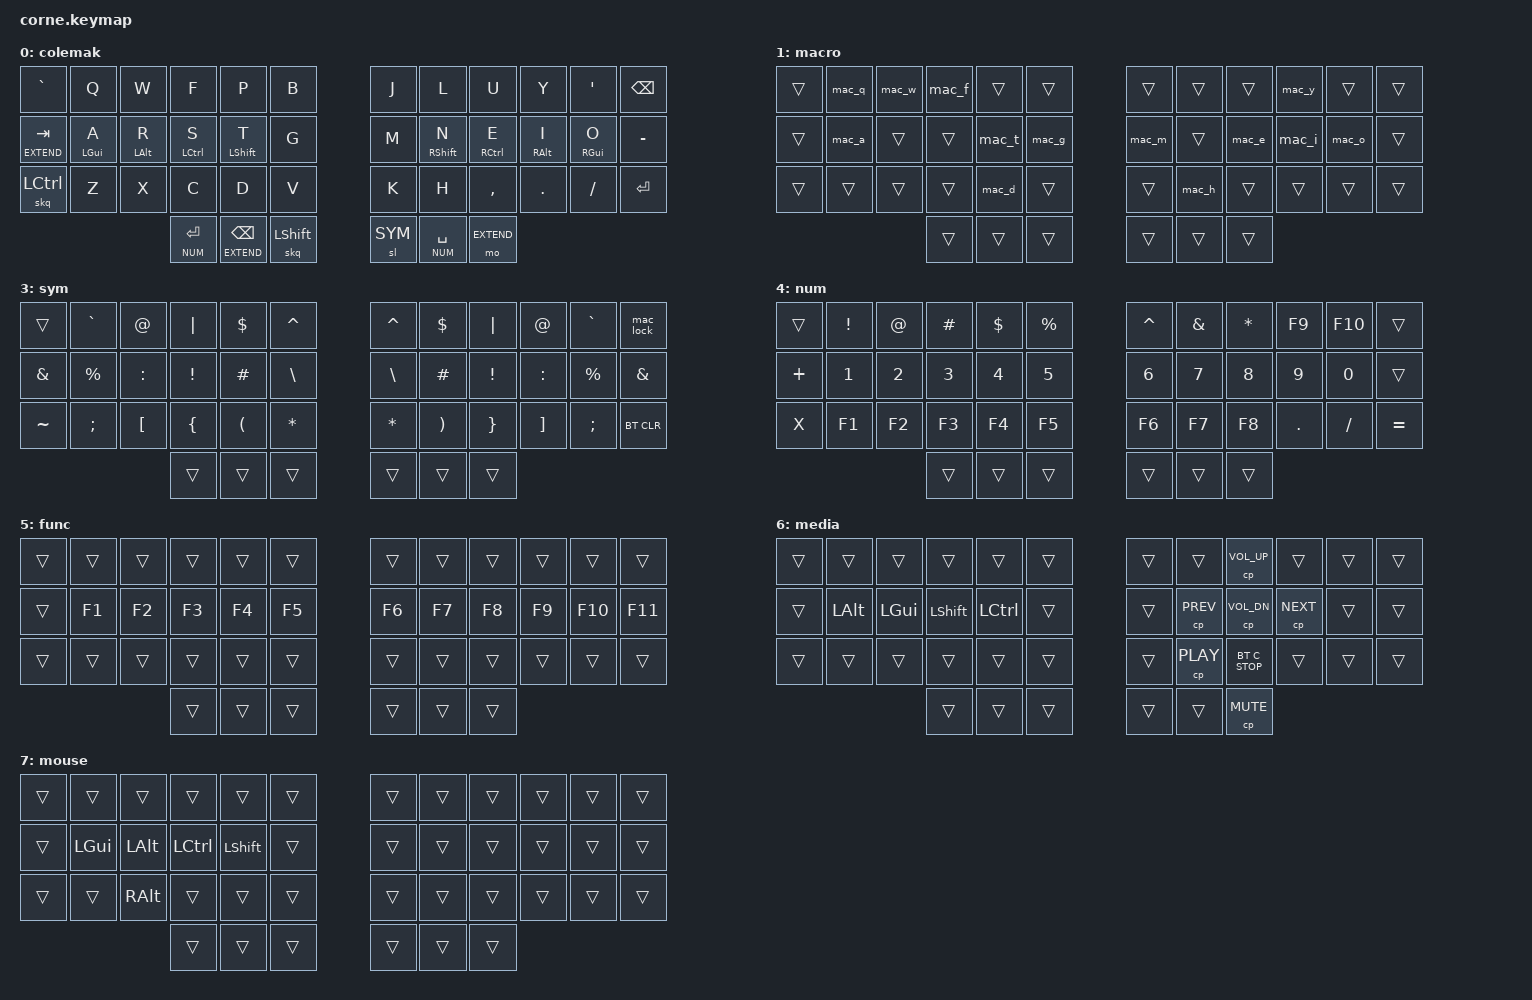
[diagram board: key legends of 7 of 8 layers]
#include <behaviors.dtsi>
#include <dt-bindings/zmk/keys.h>
#include <dt-bindings/zmk/bt.h>
#include <dt-bindings/zmk/ext_power.h>
#include <dt-bindings/zmk/outputs.h>

// Layer Definitions
#define COLEMAK 0
#define MACRO 1
#define EXTEND 2
#define SYM 3
#define NUM 4
#define FUNC 5
#define MEDIA 6
#define MOUSE 7

// Macros
#define AS(keycode) &as LS(keycode) keycode     // Autoshift Macro				

// To do
// - find a place for FUNC, MEDIA, and MOUSE to be toggled, maybe both thumbs toggles a selection layer?

// Backspace/delete multiple on double tap hold
&lt {
    tapping-term-ms = <250>;
    quick_tap_ms = <200>;
    flavor = "tap-preferred";
};

/ {
    // Behavior configuration from https://zmk.dev/docs/behaviors/hold-tap
    behaviors {
        as: auto_shift {
            compatible = "zmk,behavior-hold-tap";
            label = "AUTO_SHIFT";
            #binding-cells = <2>;
            tapping_term_ms = <200>;
            quick_tap_ms = <0>;
            flavor = "tap-preferred";
            bindings = <&kp>, <&kp>;
        };
        hm: homerow {
            compatible = "zmk,behavior-hold-tap";
            label = "HOMEROW_MODS";
            #binding-cells = <2>;
            tapping-term-ms = <300>;    // <---[[moderate duration]]
            quick-tap-ms = <0>;
            flavor = "tap-preferred";
            bindings = <&kp>, <&kp>;
        };
        hshft: homerow_shift {
            compatible = "zmk,behavior-hold-tap";
            label = "HOMEROW_MODS_SHIFT";
            #binding-cells = <2>;
            tapping-term-ms = <200>;
            quick-tap-ms = <199>;
            flavor = "tap-preferred";
            bindings = <&kp>, <&kp>;
        };
        ht_tp: holdtap_tappreferred {
            compatible = "zmk,behavior-hold-tap";
            label = "HOLD_TAP_TAP_PREFERRED";
            #binding-cells = <2>;
            flavor = "tap-preferred";
            tapping-term-ms = <200>;
            quick-tap-ms = <0>;
            bindings = <&kp>, <&kp>;
        };
        skq: sticky_key_quick_release {
            compatible = "zmk,behavior-sticky-key";
            label = "STICKY_KEY_QUICK_RELEASE";
            #binding-cells = <1>;
            bindings = <&kp>;
            release-after-ms = <1000>;
            quick-release;
        };
        hltr: hold_layer_tap_repeat {
            label = "HOLD_LAYER_TAP_REPEAT";
            #binding-cells = <2>;
            compatible = "zmk,behavior-hold-tap";
            bindings = <&mo>, <&key_repeat>;
            tapping-term-ms = <120>;
            flavor = "tap-preferred";
        };
        hmtsk: hold_mod_tap_sticky_key {
            label = "HOLD_MOD_TAP_STICKY_KEY";
            #binding-cells = <2>;
            compatible = "zmk,behavior-hold-tap";
            bindings = <&kp>, <&skq>;
            tapping-term-ms = <120>;
            flavor = "tap-preferred";
        };
        hltsk: hold_layer_tap_sticky_key {
            label = "HOLD_LAYER_TAP_STICKY_KEY";
            #binding-cells = <2>;
            compatible = "zmk,behavior-hold-tap";
            bindings = <&mo>, <&skq>;
            tapping-term-ms = <120>;
            flavor = "tap-preferred";
        };
        hltsl: hold_layer_tap_sticky_layer {
            label = "HOLD_LAYER_TAP_STICKY_LAYER";
            #binding-cells = <2>;
            compatible = "zmk,behavior-hold-tap";
            bindings = <&mo>, <&sl>;
            tapping-term-ms = <120>;
            flavor = "tap-preferred";
        };
    };
   
    combos {
        compatible = "zmk,combos";
        combo_cd_paste {
            timeout-ms = <50>;
            key-positions = <27 28>;
            bindings = <&kp LC(V)>;
        };
        combo_commadot_enter {
            timeout-ms = <50>;
            key-positions = <32 33>;
            bindings = <&kp ENTER>;
        };        
        combo_dotslash_dotdotslash {
            timeout-ms = <50>;
            key-positions = <33 34>;
            bindings = <&mac_dotslash>;
        };      
        combo_insidethumbs_capsword {
            timeout-ms = <50>;
            key-positions = <38 39>;
            bindings = <&caps_word>;
        };
        combo_io_backspace {
            timeout-ms = <25>;
            key-positions = <21 22>;
            bindings = <&kp BSPC>;
        };
        combo_outsidethumbs_func {
            timeout-ms = <50>;
            key-positions = <36 41>;
            bindings = <&sl FUNC>;
        };
        combo_qw_esc {
            timeout-ms = <50>;
            key-positions = <1 2>;
            bindings = <&kp ESC>;
        };
        combo_uy_repeat {
            timeout-ms = <50>;
            key-positions = <8 9>;
            bindings = <&key_repeat>;
        };
        combo_xc_copy {
            timeout-ms = <50>;
            key-positions = <26 27>;
            bindings = <&kp LC(C)>;
        };
        combo_wf_tab {
            timeout-ms = <50>;
            key-positions = <2 3>;
            bindings = <&kp TAB>;
        };
        combo_yquote_del {
            timeout-ms = <50>;
            key-positions = <9 10>;
            bindings = <&kp DEL>;
        };
        combo_zc_cut {
            timeout-ms = <50>;
            key-positions = <25 27>;
            bindings = <&kp LC(X)>;
        };
        combo_zx_undo {
            timeout-ms = <50>;
            key-positions = <25 26>;
            bindings = <&kp LC(Z)>;
        };
    };
    
    macros {
        mac_a: mac_a {
            label = "macro_a_and";
            compatible = "zmk,behavior-macro";
            #binding-cells = <0>;
            bindings = <&macro_tap &kp A &kp N &kp D>;
        };
        mac_d: mac_d {
            label = "macro_d_ould";
            compatible = "zmk,behavior-macro";
            #binding-cells = <0>;
            bindings = <&macro_tap &kp O &kp U &kp L &kp D>;
        };
        mac_e: mac_e {
            label = "macro_e_every";
            compatible = "zmk,behavior-macro";
            #binding-cells = <0>;
            bindings = <&macro_tap &kp E &kp V &kp E &kp R &kp Y>;
        };        
        mac_f: mac_f {
            label = "macro_f_for";
            compatible = "zmk,behavior-macro";
            #binding-cells = <0>;
            bindings = <&macro_tap &kp F &kp O &kp R>;
        };
        mac_g: mac_g {
            label = "macro_g_ing";
            compatible = "zmk,behavior-macro";
            #binding-cells = <0>;
            bindings = <&macro_tap &kp I &kp N &kp G>;
        };
        mac_h: mac_h {
            label = "macro_h_here";
            compatible = "zmk,behavior-macro";
            #binding-cells = <0>;
            bindings = <&macro_tap &kp H &kp E &kp R &kp E>;
        };
        mac_i: mac_i {
            label = "macro_i_ion";
            compatible = "zmk,behavior-macro";
            #binding-cells = <0>;
            bindings = <&macro_tap &kp I &kp O &kp N>;
        };
        mac_m: mac_m {
            label = "macro_m_ment";
            compatible = "zmk,behavior-macro";
            #binding-cells = <0>;
            bindings = <&macro_tap &kp M &kp E &kp N &kp T>;
        };
        mac_o: mac_o {
            label = "macro_o_ough";
            compatible = "zmk,behavior-macro";
            #binding-cells = <0>;
            bindings = <&macro_tap &kp O &kp U &kp G &kp H>;
        };
        mac_q: mac_q {
            label = "macro_q_que";
            compatible = "zmk,behavior-macro";
            #binding-cells = <0>;
            bindings = <&macro_tap &kp Q &kp U &kp E>;
        };
        mac_t: mac_t {
            label = "macro_t_the";
            compatible = "zmk,behavior-macro";
            #binding-cells = <0>;
            bindings = <&macro_tap &kp T &kp H &kp E>;
        };
        mac_w: mac_w {
            label = "macro_w_with";
            compatible = "zmk,behavior-macro";
            #binding-cells = <0>;
            bindings = <&macro_tap &kp W &kp I &kp T &kp H>;
        };
        mac_y: mac_y {
            label = "macro_y_you";
            compatible = "zmk,behavior-macro";
            #binding-cells = <0>;
            bindings = <&macro_tap &kp Y &kp O &kp U>;
        };
        mac_dotslash: mac_dotslash {
            label = "mac_dotslash";
            compatible = "zmk,behavior-macro";
            #binding-cells = <0>;
            bindings = <&macro_tap &kp DOT &kp DOT &kp FSLH>;
        };    
        mac_lock: mac_lock {
            label = "macro_lock";
            compatible = "zmk,behavior-macro";
            #binding-cells = <0>;
            bindings 
                = <&macro_press &kp LGUI>
                , <&macro_tap &kp L>
                , <&macro_release &kp LGUI>
                ;
        };
        mac_obkt: mac_obkt {
            label = "mac_open_brackets";
            compatible = "zmk,behavior-macro";
            #binding-cells = <0>;
            bindings = <&macro_tap &kp LBKT &kp RBKT &kp LEFT>;
        };    
        mac_obrc: mac_obrc {
            label = "mac_open_braces";
            compatible = "zmk,behavior-macro";
            #binding-cells = <0>;
            bindings = <&macro_tap &kp LBRC &kp RBRC &kp LEFT>;
        };    
        mac_opar: mac_opar {
            label = "mac_open_parentheses";
            compatible = "zmk,behavior-macro";
            #binding-cells = <0>;
            bindings = <&macro_tap &kp LPAR &kp RPAR &kp LEFT>;
        };
    
    };
    
// Keymap configuration (Colemak-DHm)
    keymap {
        compatible = "zmk,keymap";
        
        colemak {
// -----------------------------------------------------------------------------------------------------------------------------
// |   `        |   Q   |   W   |   F   |   P   |   B   | # |   J   |   L   |   U   |   Y   |   '    | BSPC  |
// | TAB/EXTEND |   A   |   R   |   S   |   T   |   G   | # |   M   |   N   |   E   |   I   |   O    |   ;   |
// | CTRL       |   Z   |   X   |   C   |   D   |   V   | # |   K   |   H   |   ,   |   .   |   /    | ENTER/SHIFT |
//                         | NUM |  BSPC/EXTEND | SHIFT | # |  SYM  |  SPC/NUM  |  MACRO  |  

            bindings = <   
&kp GRAVE           &kp Q            &kp W       &kp F           &kp P            &kp B                &kp J    &kp L          &kp U           &kp Y        &kp APOS      &kp BSPC
&lt EXTEND TAB      &hm LGUI A       &hm LALT R  &hm LCTRL S     &hshft LSHFT T   &kp G                &kp M    &hm RSHFT N    &hshft RCTRL E  &hm RALT I   &hm RGUI O    &kp MINUS
&skq LCTRL          &kp Z            &kp X       &kp C           &kp D            &kp V                &kp K    &kp H          &kp COMMA       &kp DOT      &kp FSLH      &kp ENTER
                                                 &lt NUM ENTER   &lt EXTEND BSPC  &skq LSHFT           &sl SYM  &lt NUM SPACE  &mo EXTEND
            >; 
        };
        
        macro {
// -----------------------------------------------------------------------------------------------------------------------------
// |     |   que  |  with |  for  |   P   |   B   | # |   J   |   L   |   U   |  you  |   ;    |       |
// |     |   and  |   R   |   S   |  the  |  ing  | # |  ment |   N   | every |  ion  |  ough  |       |
// |     |   Z    | email | email |  ould |   V   | # |   K   |  here |   ,   |   .   |   /    |       |
//                        |       |       |       | # |       |       |  STK  |

            bindings = <
&trans         &mac_q      &mac_w      &mac_f    &trans     &trans                &trans    &trans    &trans        &mac_y        &trans      &trans
&trans         &mac_a      &trans      &trans    &mac_t     &mac_g                &mac_m    &trans    &mac_e        &mac_i        &mac_o      &trans
&trans         &trans      &trans      &trans    &mac_d     &trans                &trans    &mac_h    &trans        &trans        &trans      &trans
                                       &trans    &trans     &trans                &trans    &trans    &trans
            >;
        };                

        extend {
// -------------------------------------------------------------------------------------------
// | ESC  | PREV | PLAY | NEXT  | PSCRN | RESET | # | RESET  | HOME | UP   | END   | DELETE |      |
// | HELD | LGUI | LALT | LCTRL | LSHFT |       | # | PG_UP | LEFT | DOWN | RIGHT | BSPC   |      |
// |      | UNDO | CUT  | COPY  | PASTE |       | # | PG_DN | VOLD | MUTE | VOLU  | DELETE |      |
//                      |       | HELD  |       | # |       |      |      |

            bindings = <
&kp ESC    &kp K_PREV &kp K_PP   &kp K_NEXT &kp PSCRN   &bootloader   &bootloader   &kp HOME      &kp UP       &kp END      &kp DEL     &trans
&trans     &kp LGUI   &kp LALT   &kp LCTRL  &kp LSHFT   &trans        &kp PG_UP     &kp LEFT      &kp DOWN     &kp RIGHT    &kp BSPC    &trans
&trans     &kp LC(Z)  &kp LC(X)  &kp LC(C)  &kp LC(V)   &trans        &kp PG_DN     &kp K_VOL_DN  &kp K_MUTE   &kp K_VOL_UP &kp DEL
                                 &trans     &trans      &trans        &trans        &trans        &trans
            >;
        };

        sym {
// ------------------------------------------------------------------------------
// |     |  `  |  @  |  |  |  $  |  ^  | # |  ^  |  $  |  |  |  @  |  `  | LOCK |
// |  &  |  %  |  :  |  !  |  #  |  \  | # |  \  |  #  |  !  |  :  |  %  |  &   |
// |  ~  |  ;  |  [  |  {  |  (  |  *  | # |  *  |  )  |  }  |  ]  |  ;  |BT_CLR|
//                   |     |     |     | # | STK |     |     | 

            bindings = <
&trans     &kp GRAVE  &kp AT     &kp PIPE   &kp DLLR   &kp CARET        &kp CARET  &kp DLLR   &kp PIPE  &kp AT     &kp GRAVE  &mac_lock
&kp AMPS   &kp PRCNT  &kp COLON  &kp EXCL   &kp HASH   &kp BSLH         &kp BSLH   &kp HASH   &kp EXCL  &kp COLON  &kp PRCNT  &kp AMPS
&kp TILDE  &kp SEMI   &kp LBKT   &kp LBRC   &kp LPAR   &kp STAR         &kp STAR   &kp RPAR   &kp RBRC  &kp RBKT   &kp SEMI   &bt BT_CLR
                                 &trans     &trans     &trans           &trans     &trans     &trans
            >;
        };
       
        num {
// -----------------------------------------------------------------------------
// |     |  !  |  @  |  #  |  $  |  %  | # |  ^  |  &  |  *  |  F9 | F10 |     |
// |  +  |  1  |  2  |  3  |  4  |  5  | # |  6  |  7  |  8  |  9  |  0  |     |
// |  x  |  F1 |  F2 |  F3 |  F4 |  F5 | # |  F6 |  F7 |  F8 |  .  |  /  |  =  |
//                   |     |     |     | # |     | HLD |     |

            bindings = <
&trans    &kp EXCL  &kp AT    &kp HASH  &kp DLLR  &kp PRCNT     &kp CARET  &kp AMPS  &kp STAR   &kp F9     &kp F10    &trans
&kp PLUS  &kp N1    &kp N2    &kp N3    &kp N4    &kp N5        &kp N6     &kp N7    &kp N8     &kp N9     &kp N0     &trans
&kp X     &kp F1    &kp F2    &kp F3    &kp F4    &kp F5        &kp F6     &kp F7    &kp F8     &kp DOT    &kp FSLH   &kp EQUAL
                              &trans    &trans    &trans        &trans     &trans    &trans
            >;
        };
        
        func {
// ------------------------------------------------------------------------------------------
// |     |      |      |       |      |      | # |      |      |      |      |       |       |
// |     |  F1  |  F2  |  F3   |  F4  |  F5  | # |  F6  |  F7  |  F8  |  F9  |  F10  |  F11  |
// |     |      |      |       |      |      | # |      |      |      |      |       |       |
//                     |       |      |      | # |      |      |      |

            bindings = <
&trans  &trans    &trans    &trans      &trans        &trans              &trans  &trans     &trans     &trans    &trans     &trans
&trans  &kp F1    &kp F2    &kp F3      &kp F4        &kp F5              &kp F6  &kp F7     &kp F8     &kp F9    &kp F10    &kp F11
&trans  &trans    &trans    &trans      &trans        &trans              &trans  &trans     &trans     &trans    &trans     &trans
                            &trans      &trans        &trans              &trans  &trans     &trans
            >;
        };

        media {
// -----------------------------------------------------------------------------------------------------
// |     |      |      |       |       |      | # |      |        | VOL_U  |       |      |     |
// |     | LALT | LGUI | LSHFT | LCTRL |      | # |      | PREV   | VOL_D  | NEXT  |      |     |
// |     |      |      |       |       |      | # |      | PLAY   | STOP   |       |      |     |
//                     | HELD  |       |      | # |      |        | MUTE   |

            bindings = <
&trans  &trans    &trans    &trans     &trans     &trans        &trans      &trans      &cp C_VOL_UP  &trans       &trans   &trans
&trans  &kp LALT  &kp LGUI  &kp LSHFT  &kp LCTRL  &trans        &trans      &cp C_PREV  &cp C_VOL_DN  &cp C_NEXT   &trans   &trans
&trans  &trans    &trans    &trans     &trans     &trans        &trans      &cp C_PLAY  &bt C_STOP    &trans       &trans   &trans
                            &trans     &trans     &trans        &trans      &trans      &cp C_MUTE
            >;
        };

// TODO
// Add mouse keys when implemented in ZMK

        mouse {
// ------------------------------------------------------------------------------------
// |     |      |      |       |       |      | # |     |     |     |     |     |     |
// |     | LGUI | LALT | LCTRL | LSHFT |      | # |     |     |     |     |     |     |
// |     |      | RALT |       |       |      | # |     |     |     |     |     |     |
//                     |       |       | HELD | # |     |     |     |

             bindings = <
&trans  &trans    &trans    &trans     &trans     &trans        &trans  &trans  &trans  &trans  &trans  &trans
&trans  &kp LGUI  &kp LALT  &kp LCTRL  &kp LSHFT  &trans        &trans  &trans  &trans  &trans  &trans  &trans
&trans  &trans    &kp RALT  &trans     &trans     &trans        &trans  &trans  &trans  &trans  &trans  &trans
                            &trans     &trans     &trans        &trans  &trans  &trans
            >;
        };

    };
};
